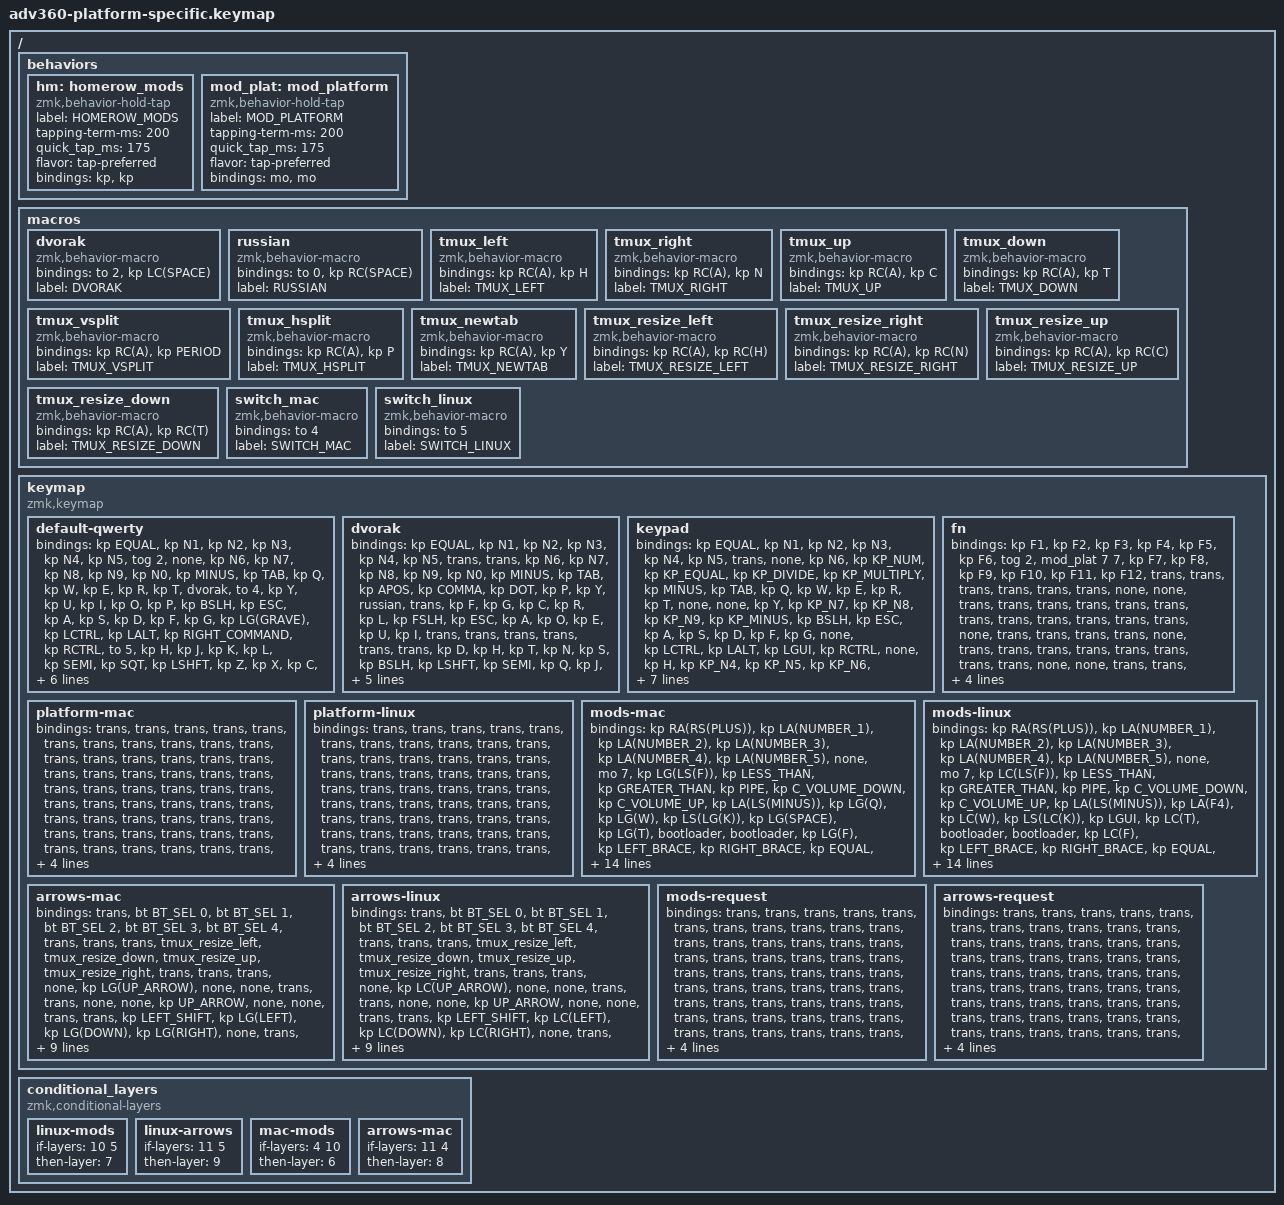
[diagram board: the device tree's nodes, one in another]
/*
 * Copyright (c) 2020 The ZMK Contributors
 *
 * SPDX-License-Identifier: MIT
 */
/* Platform-Specific Configuration for Advantage 360 Pro
 *
 * This keymap implements dual-platform support for Linux and macOS.
 * It includes separate mod layers for each platform with appropriate
 * modifier key bindings for common shortcuts.
 *
 * Layer Structure:
 * 0: Base QWERTY
 * 1: Dvorak
 * 2: Keypad
 * 3: Function Keys
 * 4: Mod Layer - Mac (default)
 * 5: Arrows & TMUX
 * 6: Mod Layer - Linux
 */

#include <behaviors.dtsi>
#include <dt-bindings/zmk/backlight.h>
#include <dt-bindings/zmk/bt.h>
#include <dt-bindings/zmk/keys.h>
#include <dt-bindings/zmk/rgb.h>

/ {
    behaviors {
        #include "macros.dtsi"
    #include "version.dtsi"

        hm: homerow_mods {
            compatible = "zmk,behavior-hold-tap";
            label = "HOMEROW_MODS";
            #binding-cells = <2>;
            tapping-term-ms = <200>;
            quick_tap_ms = <175>;
            flavor = "tap-preferred";
            bindings = <&kp>, <&kp>;
        };

        // Platform-aware mod key: tap for Mac layer, hold for Linux layer

        mod_plat: mod_platform {
            compatible = "zmk,behavior-hold-tap";
            label = "MOD_PLATFORM";
            #binding-cells = <2>;
            tapping-term-ms = <200>;
            quick_tap_ms = <175>;
            flavor = "tap-preferred";
            bindings = <&mo>, <&mo>;
        };
    };

    macros {
        dvorak: dvorak {
            compatible = "zmk,behavior-macro";
            #binding-cells = <0>;
            bindings = <&to 2 &kp LC(SPACE)>;
            label = "DVORAK";
        };

        russian: russian {
            compatible = "zmk,behavior-macro";
            #binding-cells = <0>;
            bindings = <&to 0 &kp RC(SPACE)>;
            label = "RUSSIAN";
        };

        tmux_left: tmux_left {
            compatible = "zmk,behavior-macro";
            #binding-cells = <0>;
            bindings = <&kp RC(A) &kp H>;
            label = "TMUX_LEFT";
        };

        tmux_right: tmux_right {
            compatible = "zmk,behavior-macro";
            #binding-cells = <0>;
            bindings = <&kp RC(A) &kp N>;
            label = "TMUX_RIGHT";
        };

        tmux_up: tmux_up {
            compatible = "zmk,behavior-macro";
            #binding-cells = <0>;
            bindings = <&kp RC(A) &kp C>;
            label = "TMUX_UP";
        };

        tmux_down: tmux_down {
            compatible = "zmk,behavior-macro";
            #binding-cells = <0>;
            bindings = <&kp RC(A) &kp T>;
            label = "TMUX_DOWN";
        };

        tmux_vsplit: tmux_vsplit {
            compatible = "zmk,behavior-macro";
            #binding-cells = <0>;
            bindings = <&kp RC(A) &kp PERIOD>;
            label = "TMUX_VSPLIT";
        };

        tmux_hsplit: tmux_hsplit {
            compatible = "zmk,behavior-macro";
            #binding-cells = <0>;
            bindings = <&kp RC(A) &kp P>;
            label = "TMUX_HSPLIT";
        };

        tmux_newtab: tmux_newtab {
            compatible = "zmk,behavior-macro";
            #binding-cells = <0>;
            bindings = <&kp RC(A) &kp Y>;
            label = "TMUX_NEWTAB";
        };

        tmux_resize_left: tmux_resize_left {
            compatible = "zmk,behavior-macro";
            #binding-cells = <0>;
            bindings = <&kp RC(A) &kp RC(H)>;
            label = "TMUX_RESIZE_LEFT";
        };

        tmux_resize_right: tmux_resize_right {
            compatible = "zmk,behavior-macro";
            #binding-cells = <0>;
            bindings = <&kp RC(A) &kp RC(N)>;
            label = "TMUX_RESIZE_RIGHT";
        };

        tmux_resize_up: tmux_resize_up {
            compatible = "zmk,behavior-macro";
            #binding-cells = <0>;
            bindings = <&kp RC(A) &kp RC(C)>;
            label = "TMUX_RESIZE_UP";
        };

        tmux_resize_down: tmux_resize_down {
            compatible = "zmk,behavior-macro";
            #binding-cells = <0>;
            bindings = <&kp RC(A) &kp RC(T)>;
            label = "TMUX_RESIZE_DOWN";
        };

        // Platform switching macros

        switch_mac: switch_mac {
            compatible = "zmk,behavior-macro";
            #binding-cells = <0>;
            bindings = <&to 4>;  // Return to base (uses Mac mod layer 4)
            label = "SWITCH_MAC";
        };

        switch_linux: switch_linux {
            compatible = "zmk,behavior-macro";
            #binding-cells = <0>;
            bindings = <&to 5>;  // Base layer will use Linux mod layer 6 when &mo 6 is pressed
            label = "SWITCH_LINUX";
        };
    };

    keymap {
        compatible = "zmk,keymap";

        default-qwerty {
            bindings = <
&kp EQUAL  &kp N1     &kp N2    &kp N3    &kp N4     &kp N5  &tog 2                                                                       &none      &kp N6  &kp N7  &kp N8     &kp N9    &kp N0    &kp MINUS
&kp TAB    &kp Q      &kp W     &kp E     &kp R      &kp T   &dvorak                                                                      &to 4      &kp Y   &kp U   &kp I      &kp O     &kp P     &kp BSLH
&kp ESC    &kp A      &kp S     &kp D     &kp F      &kp G   &kp LG(GRAVE)  &kp LCTRL      &kp LALT      &kp RIGHT_COMMAND  &kp RCTRL     &to 5      &kp H   &kp J   &kp K      &kp L     &kp SEMI  &kp SQT
&kp LSHFT  &kp Z      &kp X     &kp C     &kp V      &kp B                                 &kp HOME      &kp PG_UP                                   &kp N   &kp M   &kp COMMA  &kp DOT   &kp FSLH  &kp RSHFT
&mo 3      &kp GRAVE  &kp CAPS  &kp LEFT  &kp RIGHT          &kp BACKSPACE  &lt 10 DELETE  &kp END       &kp PAGE_DOWN      &lt 11 ENTER  &kp SPACE          &kp UP  &kp DOWN   &kp LBKT  &kp RBKT  &tog 9
            >;
        };

        dvorak {
            bindings = <
&kp EQUAL  &kp N1     &kp N2     &kp N3   &kp N4  &kp N5  &trans                                        &trans  &kp N6  &kp N7  &kp N8  &kp N9    &kp N0    &kp MINUS
&kp TAB    &kp APOS   &kp COMMA  &kp DOT  &kp P   &kp Y   &russian                                      &trans  &kp F   &kp G   &kp C   &kp R     &kp L     &kp FSLH
&kp ESC    &kp A      &kp O      &kp E    &kp U   &kp I   &trans    &trans  &trans      &trans  &trans  &trans  &kp D   &kp H   &kp T   &kp N     &kp S     &kp BSLH
&kp LSHFT  &kp SEMI   &kp Q      &kp J    &kp K   &kp X                     &trans      &trans                  &kp B   &kp M   &kp W   &kp V     &kp Z     &kp RSHFT
&trans     &kp GRAVE  &trans     &trans   &trans          &trans    &trans  &trans      &trans  &trans  &trans          &trans  &trans  &kp LBKT  &kp RBKT  &trans
            >;
        };

        keypad {
            bindings = <
&kp EQUAL  &kp N1     &kp N2    &kp N3    &kp N4     &kp N5  &trans                                                   &none      &kp N6  &kp KP_NUM  &kp KP_EQUAL  &kp KP_DIVIDE  &kp KP_MULTIPLY  &kp MINUS
&kp TAB    &kp Q      &kp W     &kp E     &kp R      &kp T   &none                                                    &none      &kp Y   &kp KP_N7   &kp KP_N8     &kp KP_N9      &kp KP_MINUS     &kp BSLH
&kp ESC    &kp A      &kp S     &kp D     &kp F      &kp G   &none     &kp LCTRL  &kp LALT      &kp LGUI   &kp RCTRL  &none      &kp H   &kp KP_N4   &kp KP_N5     &kp KP_N6      &kp KP_PLUS      &kp SQT
&kp LSHFT  &kp Z      &kp X     &kp C     &kp V      &kp B                        &kp HOME      &kp PG_UP                        &kp N   &kp KP_N1   &kp KP_N2     &kp KP_N3      &kp KP_ENTER     &kp RSHFT
&mo 3      &kp GRAVE  &kp CAPS  &kp LEFT  &kp RIGHT          &kp BSPC  &kp DEL    &kp END       &kp PG_DN  &kp ENTER  &kp KP_N0          &kp UP      &kp DOWN      &kp KP_DOT     &none            &mo 3
            >;
        };

        fn {
            bindings = <
&kp F1  &kp F2  &kp F3  &kp F4  &kp F5  &kp F6  &tog 2                                      &mod_plat 7 7  &kp F7  &kp F8  &kp F9  &kp F10  &kp F11  &kp F12
&trans  &trans  &trans  &trans  &trans  &trans  &none                                       &none          &trans  &trans  &trans  &trans   &trans   &trans
&trans  &trans  &trans  &trans  &trans  &trans  &none   &trans  &trans      &trans  &trans  &none          &trans  &trans  &trans  &trans   &trans   &trans
&trans  &trans  &none   &none   &trans  &trans                  &trans      &trans                         &trans  &trans  &trans  &trans   &trans   &trans
&trans  &trans  &trans  &trans  &trans          &trans  &trans  &trans      &trans  &trans  &trans                 &trans  &trans  &trans   &trans   &trans
            >;
        };

        platform-mac {
            bindings = <
&trans  &trans  &trans  &trans  &trans  &trans  &trans                                      &trans  &trans  &trans  &trans  &trans  &trans  &trans
&trans  &trans  &trans  &trans  &trans  &trans  &trans                                      &trans  &trans  &trans  &trans  &trans  &trans  &trans
&trans  &trans  &trans  &trans  &trans  &trans  &trans  &trans  &trans      &trans  &trans  &trans  &trans  &trans  &trans  &trans  &trans  &trans
&trans  &trans  &trans  &trans  &trans  &trans                  &trans      &trans                  &trans  &trans  &trans  &trans  &trans  &trans
&trans  &trans  &trans  &trans  &trans          &trans  &trans  &trans      &trans  &trans  &trans          &trans  &trans  &trans  &trans  &trans
            >;
        };

        platform-linux {
            bindings = <
&trans  &trans  &trans  &trans  &trans  &trans  &trans                                      &trans  &trans  &trans  &trans  &trans  &trans  &trans
&trans  &trans  &trans  &trans  &trans  &trans  &trans                                      &trans  &trans  &trans  &trans  &trans  &trans  &trans
&trans  &trans  &trans  &trans  &trans  &trans  &trans  &trans  &trans      &trans  &trans  &trans  &trans  &trans  &trans  &trans  &trans  &trans
&trans  &trans  &trans  &trans  &trans  &trans                  &trans      &trans                  &trans  &trans  &trans  &trans  &trans  &trans
&trans  &trans  &trans  &trans  &trans          &trans  &trans  &trans      &trans  &trans  &trans          &trans  &trans  &trans  &trans  &trans
            >;
        };

        mods-mac {
            // Mac-specific shortcuts (Cmd-based)

            bindings = <
&kp RA(RS(PLUS))   &kp LA(NUMBER_1)  &kp LA(NUMBER_2)   &kp LA(NUMBER_3)  &kp LA(NUMBER_4)  &kp LA(NUMBER_5)  &none                                                          &mo 7                   &kp LG(LS(F))  &kp LESS_THAN         &kp GREATER_THAN       &kp PIPE         &kp C_VOLUME_DOWN  &kp C_VOLUME_UP
&kp LA(LS(MINUS))  &kp LG(Q)         &kp LG(W)          &kp LS(LG(K))     &kp LG(SPACE)     &kp LG(T)         &bootloader                                                    &bootloader             &kp LG(F)      &kp LEFT_BRACE        &kp RIGHT_BRACE        &kp EQUAL        &kp C_MUTE         &kp C_PLAY_PAUSE
&none              &kp LG(S)         &kp LG(O)          &kp LG(C)         &kp LG(V)         &kp F12           &none        &none  &none      &bt BT_CLR       &none          &rgb_ug RGB_MEFS_CMD 5  &none          &kp LEFT_PARENTHESIS  &kp RIGHT_PARENTHESIS  &kp EXCLAMATION  &kp C_PREVIOUS     &kp C_NEXT
&none              &kp LC(MINUS)     &kp RS(RC(MINUS))  &kp LG(Z)         &kp LS(LG(Z))     &none                                 &none      &bl BL_TOG                                              &none          &kp LEFT_BRACKET      &kp RIGHT_BRACKET      &kp PLUS         &none              &none
&none              &none             &kp LA(LS(SEMI))   &kp LA(COMMA)     &kp LA(SLASH)                       &none        &none  &none      &rgb_ug RGB_TOG  &kp LG(ENTER)  &kp LG(SLASH)                          &kp LA(H)             &kp LA(J)              &kp RA(K)        &kp LA(L)          &none
            >;
        };

        mods-linux {
            // Linux-specific shortcuts (Ctrl-based)

            bindings = <
&kp RA(RS(PLUS))   &kp LA(NUMBER_1)  &kp LA(NUMBER_2)   &kp LA(NUMBER_3)  &kp LA(NUMBER_4)  &kp LA(NUMBER_5)  &none                                                          &mo 7                   &kp LC(LS(F))  &kp LESS_THAN         &kp GREATER_THAN       &kp PIPE         &kp C_VOLUME_DOWN  &kp C_VOLUME_UP
&kp LA(LS(MINUS))  &kp LA(F4)        &kp LC(W)          &kp LS(LC(K))     &kp LGUI          &kp LC(T)         &bootloader                                                    &bootloader             &kp LC(F)      &kp LEFT_BRACE        &kp RIGHT_BRACE        &kp EQUAL        &kp C_MUTE         &kp C_PLAY_PAUSE
&none              &kp LC(S)         &kp LC(O)          &kp LC(C)         &kp LC(V)         &kp F12           &none        &none  &none      &bt BT_CLR       &none          &rgb_ug RGB_MEFS_CMD 5  &none          &kp LEFT_PARENTHESIS  &kp RIGHT_PARENTHESIS  &kp EXCLAMATION  &kp C_PREVIOUS     &kp C_NEXT
&none              &kp LC(MINUS)     &kp RS(RC(MINUS))  &kp LC(Z)         &kp LC(LS(Z))     &none                                 &none      &bl BL_TOG                                              &none          &kp LEFT_BRACKET      &kp RIGHT_BRACKET      &kp PLUS         &none              &none
&none              &none             &kp LA(LS(SEMI))   &kp LA(COMMA)     &kp LA(SLASH)                       &none        &none  &none      &rgb_ug RGB_TOG  &kp LC(ENTER)  &kp LC(SLASH)                          &kp LA(H)             &kp LA(J)              &kp RA(K)        &kp LA(L)          &none
            >;
        };

        arrows-mac {
            bindings = <
&trans  &bt BT_SEL 0    &bt BT_SEL 1  &bt BT_SEL 2      &bt BT_SEL 3   &bt BT_SEL 4  &trans                                      &trans  &trans  &tmux_resize_left  &tmux_resize_down  &tmux_resize_up  &tmux_resize_right  &trans
&trans  &trans          &none         &kp LG(UP_ARROW)  &none          &none         &trans                                      &trans  &none   &none              &kp UP_ARROW       &none            &none               &trans
&trans  &kp LEFT_SHIFT  &kp LG(LEFT)  &kp LG(DOWN)      &kp LG(RIGHT)  &none         &trans  &trans  &trans      &trans  &trans  &trans  &none   &kp LEFT           &kp DOWN           &kp RIGHT        &kp RIGHT_ALT       &trans
&trans  &kp LEFT_ALT    &none         &none             &none          &none                         &trans      &trans                  &none   &none              &none              &none            &kp RIGHT_CONTROL   &trans
&trans  &trans          &tmux_newtab  &tmux_hsplit      &tmux_vsplit                 &trans  &trans  &trans      &trans  &trans  &trans          &tmux_left         &tmux_down         &tmux_up         &tmux_right         &trans
            >;
        };

        arrows-linux {
            bindings = <
&trans  &bt BT_SEL 0    &bt BT_SEL 1  &bt BT_SEL 2      &bt BT_SEL 3   &bt BT_SEL 4  &trans                                      &trans  &trans  &tmux_resize_left  &tmux_resize_down  &tmux_resize_up  &tmux_resize_right  &trans
&trans  &trans          &none         &kp LC(UP_ARROW)  &none          &none         &trans                                      &trans  &none   &none              &kp UP_ARROW       &none            &none               &trans
&trans  &kp LEFT_SHIFT  &kp LC(LEFT)  &kp LC(DOWN)      &kp LC(RIGHT)  &none         &trans  &trans  &trans      &trans  &trans  &trans  &none   &kp LEFT           &kp DOWN           &kp RIGHT        &kp RIGHT_ALT       &trans
&trans  &kp LEFT_ALT    &none         &none             &none          &none                         &trans      &trans                  &none   &none              &none              &none            &kp RIGHT_CONTROL   &trans
&trans  &trans          &tmux_newtab  &tmux_hsplit      &tmux_vsplit                 &trans  &trans  &trans      &trans  &trans  &trans          &tmux_left         &tmux_down         &tmux_up         &tmux_right         &trans
            >;
        };

        mods-request {
            bindings = <
&trans  &trans  &trans  &trans  &trans  &trans  &trans                                      &trans  &trans  &trans  &trans  &trans  &trans  &trans
&trans  &trans  &trans  &trans  &trans  &trans  &trans                                      &trans  &trans  &trans  &trans  &trans  &trans  &trans
&trans  &trans  &trans  &trans  &trans  &trans  &trans  &trans  &trans      &trans  &trans  &trans  &trans  &trans  &trans  &trans  &trans  &trans
&trans  &trans  &trans  &trans  &trans  &trans                  &trans      &trans                  &trans  &trans  &trans  &trans  &trans  &trans
&trans  &trans  &trans  &trans  &trans          &trans  &trans  &trans      &trans  &trans  &trans          &trans  &trans  &trans  &trans  &trans
            >;
        };

        arrows-request {
            bindings = <
&trans  &trans  &trans  &trans  &trans  &trans  &trans                                      &trans  &trans  &trans  &trans  &trans  &trans  &trans
&trans  &trans  &trans  &trans  &trans  &trans  &trans                                      &trans  &trans  &trans  &trans  &trans  &trans  &trans
&trans  &trans  &trans  &trans  &trans  &trans  &trans  &trans  &trans      &trans  &trans  &trans  &trans  &trans  &trans  &trans  &trans  &trans
&trans  &trans  &trans  &trans  &trans  &trans                  &trans      &trans                  &trans  &trans  &trans  &trans  &trans  &trans
&trans  &trans  &trans  &trans  &trans          &trans  &trans  &trans      &trans  &trans  &trans          &trans  &trans  &trans  &trans  &trans
            >;
        };
    };

    conditional_layers {
        compatible = "zmk,conditional-layers";

        linux-mods {
            if-layers = <10 5>;
            then-layer = <7>;
        };

        linux-arrows {
            if-layers = <11 5>;
            then-layer = <9>;
        };

        mac-mods {
            if-layers = <4 10>;
            then-layer = <6>;
        };

        arrows-mac {
            if-layers = <11 4>;
            then-layer = <8>;
        };
    };
};
